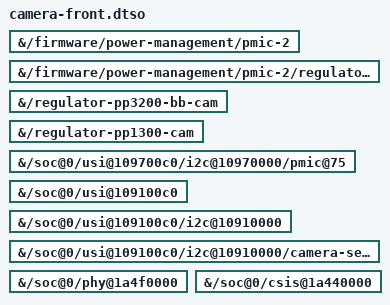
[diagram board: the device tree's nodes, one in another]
// SPDX-License-Identifier: MIT
/*
 * Bring-up only (CAMERA-PLAN.md, stage CAM7): the front camera capture path,
 * the Samsung S5K3J1 on four D-PHY lanes to CSIS link 0 and CSIS WDMA
 * context 0 (fixed focus, no lens). Enables the camera power path as
 * camera-stream-link2 does, plus PERIC0 USI2 and its I2C bus. It stacks with
 * camera-stream-link2 and camera-main: all links share WDMA context 0 and
 * the driver streams one at a time. Never apply it together with
 * camera-pwr-test.
 *
 * Nothing binds at boot: gpio_s2mpg13, slg51002_regulator, s5kgn1 (which
 * drives the S5K3J1 too), phy_gs201_mipi_dcphy_rx and gs201_csis are
 * blacklisted. Paths, not labels.
 */
/dts-v1/;
/plugin/;

&{/firmware/power-management/pmic-2} {
	status = "okay";
};

&{/firmware/power-management/pmic-2/regulators/ldo12s} {
	status = "okay";
};

&{/regulator-pp3200-bb-cam} {
	status = "okay";
};

&{/regulator-pp1300-cam} {
	status = "okay";
};

&{/soc@0/usi@109700c0/i2c@10970000/pmic@75} {
	status = "okay";
};

&{/soc@0/usi@109100c0} {
	status = "okay";
};

&{/soc@0/usi@109100c0/i2c@10910000} {
	status = "okay";
};

&{/soc@0/usi@109100c0/i2c@10910000/camera-sensor@10} {
	status = "okay";
};

&{/soc@0/phy@1a4f0000} {
	status = "okay";
};

&{/soc@0/csis@1a440000} {
	status = "okay";
};
